# STM32WB06 register map
File version: 1.0
Registers are 32-bit, read-write, reset 0x0 unless marked. A register's access mark holds for its fields unless they carry their own. Offsets are from the block's base; [hi:lo] are bit positions; {n}, {i} and the like mark numbered series.

## IWDG
Base 0x40003000
0x00 KR
  [15:0] KEY
0x04 PR
  [2:0] PR
0x08 RLR
  [11:0] RL
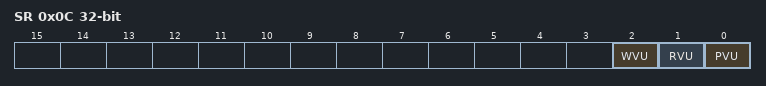
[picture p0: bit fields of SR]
0x0C SR
  [2] WVU, [1] RVU, [0] PVU
0x10 WINR
  [11:0] WIN

## RTC
Base 0x40004000
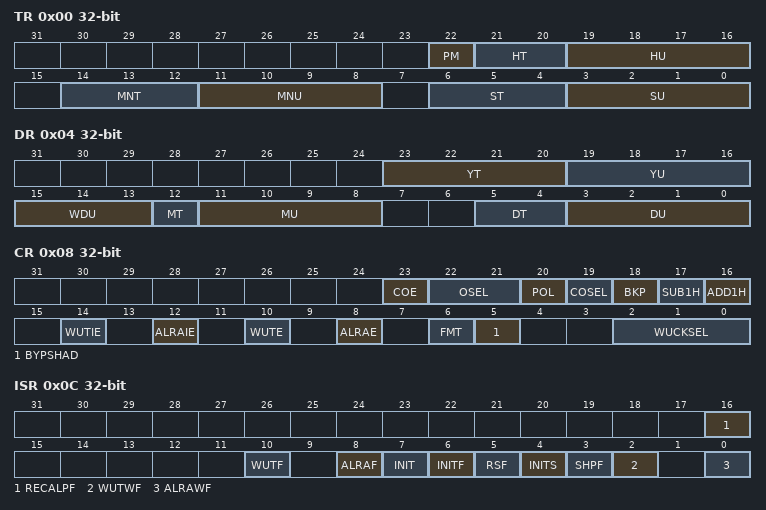
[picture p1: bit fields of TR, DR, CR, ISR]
0x00 TR
  [22] PM
    0=AM_OR_24 (AM or 24-hour format); 1=PM
  [21:20] HT
  [19:16] HU
  [14:12] MNT
  [11:8] MNU
  [6:4] ST
  [3:0] SU
0x04 DR
  [23:20] YT, [19:16] YU, [15:13] WDU, [12] MT, [11:8] MU, [5:4] DT, [3:0] DU
0x08 CR
  [23] COE
  [22:21] OSEL
    0=DISABLE (Output disabled); 1=ALMA (Alarm A output enabled); 2=ALMB (Alarm B output enabled); 3=WAKEUP (Wakeup output enabled)
  [20] POL
    0=HIGH (Pin is high when ALRAF/ALRBF/WUTF is asserted (depending on OSEL)); 1=LOW (Pin is low when ALRAF/ALRBF/WUTF is asserted (depending on OSEL))
  [19] COSEL
  [18] BKP
  [17] SUB1H
  [16] ADD1H
  [14] WUTIE
  [12] ALRAIE
  [10] WUTE
  [8] ALRAE
  [6] FMT
    0=HOURFORMAT_24HOUR (24 hour/day format); 1=AMPM (AM/PM hour format)
  [5] BYPSHAD
  [2:0] WUCKSEL
    0=DIV_16 (RTC/16 clock is selected); 1=DIV_8 (RTC/8 clock is selected); 2=DIV_4 (RTC/4 clock is selected); 3=DIV_2 (RTC/2 clock is selected); 4=CKSPRE (ck_spre (usually 1 Hz) clock is selected); 6=CKSPRE_WUT (ck_spre (usually 1 Hz) clock is selected and 2exp16 is added to the WUT counter value)
0x0C ISR
  [16] RECALPF, [10] WUTF, [8] ALRAF, [7] INIT, [6] INITF, [5] RSF, [4] INITS, [3] SHPF, [2] WUTWF, [0] ALRAWF
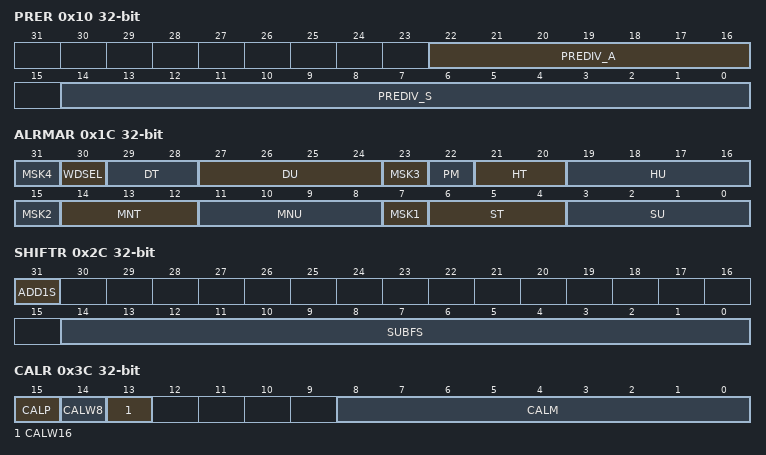
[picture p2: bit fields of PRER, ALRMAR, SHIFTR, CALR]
0x10 PRER
  [22:16] PREDIV_A, [14:0] PREDIV_S
0x14 WUTR
  [15:0] WUT
0x1C ALRMAR
  [8n-1] MSK{n} (n=1..4)
  [30] WDSEL
  [29:28] DT
  [27:24] DU
  [22] PM
    0=AM (AM or 24-hour format); 1=PM
  [21:20] HT
  [19:16] HU
  [14:12] MNT
  [11:8] MNU
  [6:4] ST
  [3:0] SU
0x24 WPR
  [7:0] KEY
0x28 SSR
  [15:0] SS
0x2C SHIFTR
  [31] ADD1S, [14:0] SUBFS
0x3C CALR
  [15] CALP
    0=NONE (No RTCCLK pulses are added); 1=SET (One RTCCLK pulse is effectively inserted every 2exp11 pulses (frequency increased by 488.5 ppm))
  [14] CALW8
  [13] CALW16
  [8:0] CALM
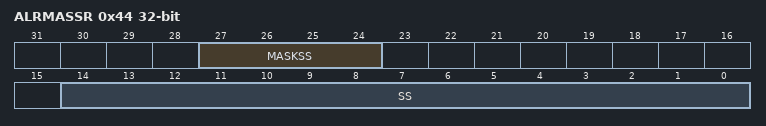
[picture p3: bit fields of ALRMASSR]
0x44 ALRMASSR
  [27:24] MASKSS, [14:0] SS
0x50 BKP0R
  [31:0] BKP
0x54 BKP1R
  [31:0] BKP

## AHBUPCONV
Base 0x40005000
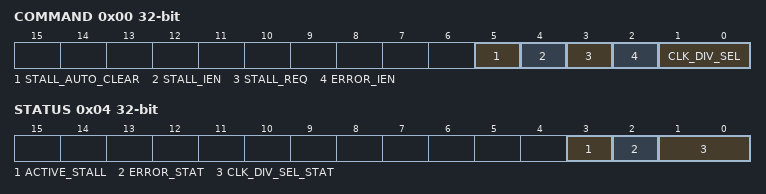
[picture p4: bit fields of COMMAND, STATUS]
0x00 COMMAND
  [5] STALL_AUTO_CLEAR, [4] STALL_IEN, [3] STALL_REQ, [2] ERROR_IEN, [1:0] CLK_DIV_SEL
0x04 STATUS
  [3] ACTIVE_STALL, [2] ERROR_STAT, [1:0] CLK_DIV_SEL_STAT

## I2C1
Base 0x41000000
Same registers: I2C2 0x41001000
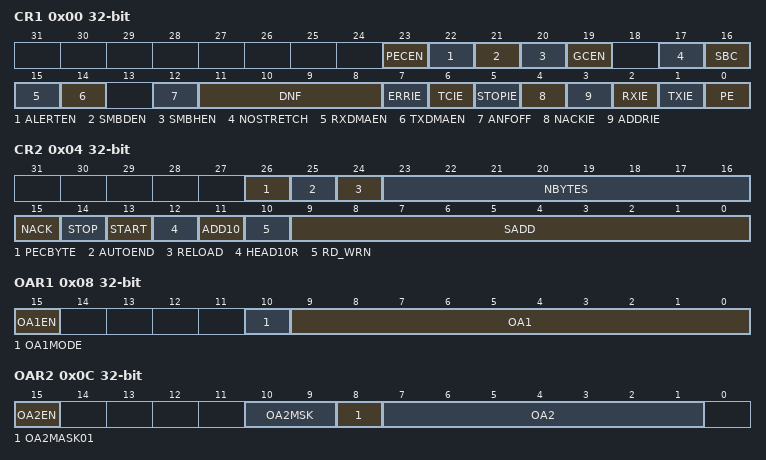
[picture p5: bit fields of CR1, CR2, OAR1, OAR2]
0x00 CR1
  [23] PECEN, [22] ALERTEN, [21] SMBDEN, [20] SMBHEN, [19] GCEN, [17] NOSTRETCH, [16] SBC, [15] RXDMAEN, [14] TXDMAEN, [12] ANFOFF, [11:8] DNF, [7] ERRIE, [6] TCIE, [5] STOPIE, [4] NACKIE, [3] ADDRIE, [2] RXIE, [1] TXIE, [0] PE
0x04 CR2
  [26] PECBYTE
  [25] AUTOEND
  [24] RELOAD
  [23:16] NBYTES
  [15] NACK
    0=ACK (ACK is sent after current received byte.); 1=NACK (NACK is sent after current received byte.)
  [14] STOP
  [13] START
  [12] HEAD10R
  [11] ADD10
    0=MODE_7BIT (Master operates in 7-bit addressing mode.); 1=MODE_10BIT (Master operates in 10-bit addressing mode.)
  [10] RD_WRN
    0=WRITE (Master request a write transfer.); 1=READ (Master request a read transfer.)
  [9:0] SADD
0x08 OAR1
  [15] OA1EN, [10] OA1MODE, [9:0] OA1
0x0C OAR2
  [15] OA2EN
  [10:9] OA2MSK
  [8] OA2MASK01 — OA2[1] is masked, Only OA2[7:2] are compared
  [7:1] OA2
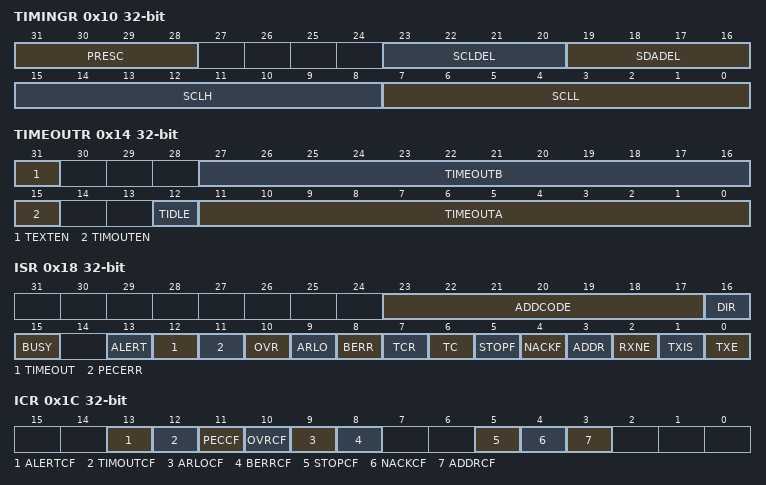
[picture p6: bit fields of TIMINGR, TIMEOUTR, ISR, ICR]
0x10 TIMINGR
  [31:28] PRESC, [23:20] SCLDEL, [19:16] SDADEL, [15:8] SCLH, [7:0] SCLL
0x14 TIMEOUTR
  [31] TEXTEN
  [27:16] TIMEOUTB
  [15] TIMOUTEN
  [12] TIDLE
    0=SCL_LOW; 1=SDA_SCL_HIGH
  [11:0] TIMEOUTA
0x18 ISR
  [23:17] ADDCODE
  [16] DIR
    0=WRITE; 1=READ
  [15] BUSY
  [13] ALERT
  [12] TIMEOUT
  [11] PECERR
  [10] OVR
  [9] ARLO
  [8] BERR
  [7] TCR
  [6] TC
  [5] STOPF
  [4] NACKF
  [3] ADDR
  [2] RXNE
  [1] TXIS
  [0] TXE
0x1C ICR
  [13] ALERTCF, [12] TIMOUTCF, [11] PECCF, [10] OVRCF, [9] ARLOCF, [8] BERRCF, [5] STOPCF, [4] NACKCF, [3] ADDRCF
0x20 PECR
  [7:0] PEC
0x24 RXDR
  [7:0] RXDATA
0x28 TXDR
  [7:0] TXDATA
